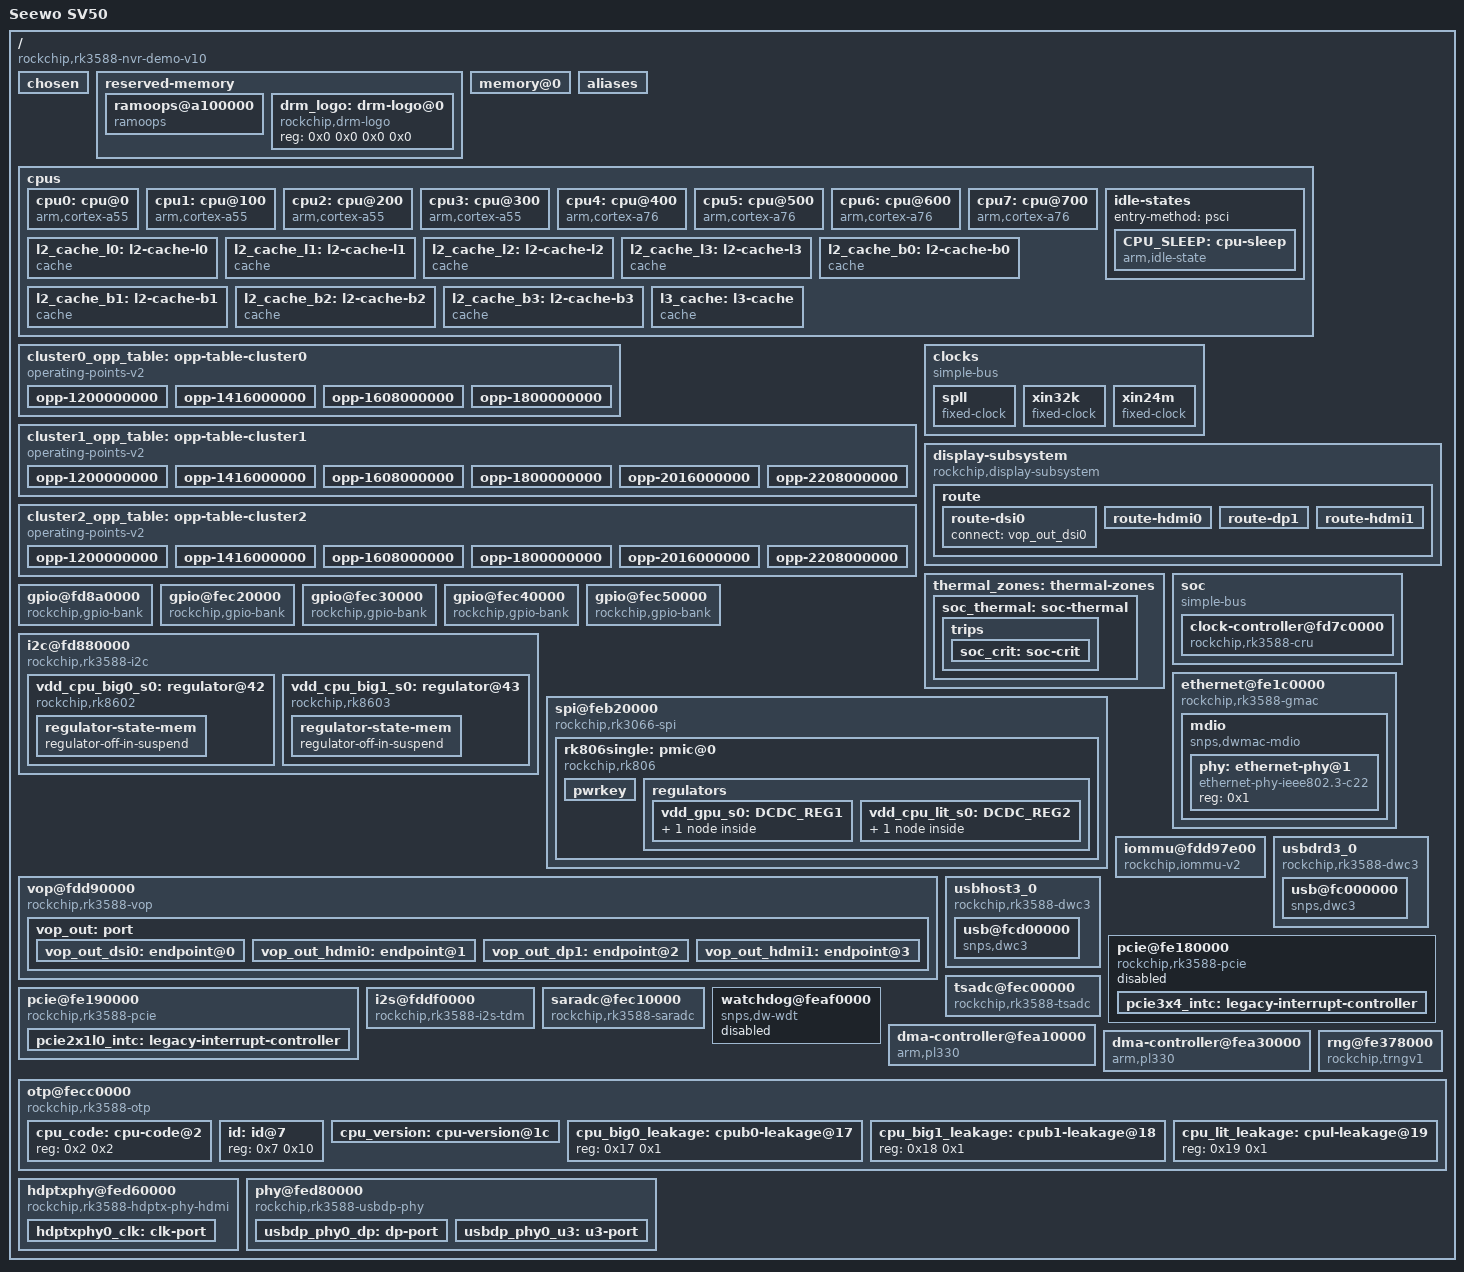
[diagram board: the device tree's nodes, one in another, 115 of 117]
// SPDX-License-Identifier: (GPL-2.0+ OR MIT)
/*
 * Device Tree Source for Rockchip RK3588 NVR Demo Board
 * Version: SV50 Board (AV.RK3588.71)
 * Converted to Linux 6.1 standard format
 */

/dts-v1/;

/ {
	compatible = "rockchip,rk3588-nvr-demo-v10", "rockchip,rk3588", "seewo,sv50";
	interrupt-parent = <&gic>;
	#address-cells = <2>;
	#size-cells = <2>;
	model = "Seewo SV50";

	chosen {
		bootargs = "storagemedia=emmc rw rootwait earlycon=uart8250,mmio32,0xfeb50000 console=ttyFIQ0 irqchip.gicv3_pseudo_nmi=0 clk_gate.always_on=1 pm_domains.always_on=1";
		stdout-path = "serial0:1500000n8";
	};

	reserved-memory {
		#address-cells = <2>;
		#size-cells = <2>;
		ranges;

		/* Reserved region from original DTB (0xa100000-0xa128000) */
		ramoops@a100000 {
			compatible = "ramoops";
			reg = <0x0 0x0a100000 0x0 0x0028000>;
			record-size = <0x10000>;
			console-size = <0x20000>;
			ftrace-size = <0x00000>;
			pmsg-size = <0x50000>;
		};

		/* DRM logo region */
		drm_logo: drm-logo@0 {
			compatible = "rockchip,drm-logo";
			reg = <0x0 0x0 0x0 0x0>;
		};
	};

	memory@0 {
		device_type = "memory";
		reg = <0x0 0x00200000 0x0 0x08200000>,
		      <0x0 0x09400000 0x0 0xe6c00000>;
	};

	aliases {
		serial0 = &uart0;
		serial2 = &uart2;
		serial5 = &uart5;
		i2c0 = &i2c0;
		i2c1 = &i2c1;
		i2c3 = &i2c3;
		i2c5 = &i2c5;
		i2c6 = &i2c6;
		spi2 = &spi2;
		dsi0 = &dsi0;
		dp1 = &dp1;
		hdmi0 = &hdmi0;
		hdmi1 = &hdmi1;
		ethernet1 = &gmac1;
		gpio0 = &gpio0;
		gpio1 = &gpio1;
		gpio2 = &gpio2;
		gpio3 = &gpio3;
		gpio4 = &gpio4;
		rkcif_mipi_lvds1 = &rkcif_mipi_lvds1;
		rkcif_mipi_lvds4 = &rkcif_mipi_lvds4;
		rkvenc0 = &rkvenc0;
		rkvenc1 = &rkvenc1;
		jpege0 = &jpege0;
		jpege1 = &jpege1;
		jpege2 = &jpege2;
		jpege3 = &jpege3;
		csi2dcphy1 = &csi2_dcphy1;
		csi2dphy1 = &csi2_dphy1;
		csi2dphy3 = &csi2_dphy3;
		hdptx0 = &hdptxphy0;
		hdptx1 = &hdptxphy1;
		hdptxhdmi0 = &hdmi_phy0;
		hdptxhdmi1 = &hdmi_phy1;
		usbdp0 = &usbdp_phy0;
		usbdp1 = &usbdp_phy1;
	};

	cpus {
		#address-cells = <1>;
		#size-cells = <0>;

		cpu0: cpu@0 {
			device_type = "cpu";
			compatible = "arm,cortex-a55";
			reg = <0x0>;
			enable-method = "psci";
			capacity-dmips-mhz = <530>;
			clocks = <&scmi_clk 0>;
			operating-points-v2 = <&cluster0_opp_table>;
			cpu-idle-states = <&CPU_SLEEP>;
			i-cache-size = <0x8000>;
			i-cache-line-size = <0x40>;
			i-cache-sets = <0x80>;
			d-cache-size = <0x8000>;
			d-cache-line-size = <0x40>;
			d-cache-sets = <0x80>;
			next-level-cache = <&l2_cache_l0>;
			#cooling-cells = <2>;
			dynamic-power-coefficient = <228>;
			cpu-supply = <&vdd_cpu_lit_s0>;
			mem-supply = <&vdd_cpu_lit_s0>;
		};

		cpu1: cpu@100 {
			device_type = "cpu";
			compatible = "arm,cortex-a55";
			reg = <0x100>;
			enable-method = "psci";
			capacity-dmips-mhz = <530>;
			clocks = <&scmi_clk 0>;
			operating-points-v2 = <&cluster0_opp_table>;
			cpu-idle-states = <&CPU_SLEEP>;
			i-cache-size = <0x8000>;
			i-cache-line-size = <0x40>;
			i-cache-sets = <0x80>;
			d-cache-size = <0x8000>;
			d-cache-line-size = <0x40>;
			d-cache-sets = <0x80>;
			next-level-cache = <&l2_cache_l1>;
		};

		cpu2: cpu@200 {
			device_type = "cpu";
			compatible = "arm,cortex-a55";
			reg = <0x200>;
			enable-method = "psci";
			capacity-dmips-mhz = <530>;
			clocks = <&scmi_clk 0>;
			operating-points-v2 = <&cluster0_opp_table>;
			cpu-idle-states = <&CPU_SLEEP>;
			i-cache-size = <0x8000>;
			i-cache-line-size = <0x40>;
			i-cache-sets = <0x80>;
			d-cache-size = <0x8000>;
			d-cache-line-size = <0x40>;
			d-cache-sets = <0x80>;
			next-level-cache = <&l2_cache_l2>;
		};

		cpu3: cpu@300 {
			device_type = "cpu";
			compatible = "arm,cortex-a55";
			reg = <0x300>;
			enable-method = "psci";
			capacity-dmips-mhz = <530>;
			clocks = <&scmi_clk 0>;
			operating-points-v2 = <&cluster0_opp_table>;
			cpu-idle-states = <&CPU_SLEEP>;
			i-cache-size = <0x8000>;
			i-cache-line-size = <0x40>;
			i-cache-sets = <0x80>;
			d-cache-size = <0x8000>;
			d-cache-line-size = <0x40>;
			d-cache-sets = <0x80>;
			next-level-cache = <&l2_cache_l3>;
		};

		cpu4: cpu@400 {
			device_type = "cpu";
			compatible = "arm,cortex-a76";
			reg = <0x400>;
			enable-method = "psci";
			capacity-dmips-mhz = <1024>;
			clocks = <&scmi_clk 2>;
			operating-points-v2 = <&cluster1_opp_table>;
			cpu-idle-states = <&CPU_SLEEP>;
			i-cache-size = <0x10000>;
			i-cache-line-size = <0x40>;
			i-cache-sets = <0x100>;
			d-cache-size = <0x10000>;
			d-cache-line-size = <0x40>;
			d-cache-sets = <0x100>;
			next-level-cache = <&l2_cache_b0>;
			#cooling-cells = <2>;
			dynamic-power-coefficient = <416>;
			cpu-supply = <&vdd_cpu_big0_s0>;
			mem-supply = <&vdd_cpu_big0_s0>;
		};

		cpu5: cpu@500 {
			device_type = "cpu";
			compatible = "arm,cortex-a76";
			reg = <0x500>;
			enable-method = "psci";
			capacity-dmips-mhz = <1024>;
			clocks = <&scmi_clk 2>;
			operating-points-v2 = <&cluster1_opp_table>;
			cpu-idle-states = <&CPU_SLEEP>;
			i-cache-size = <0x10000>;
			i-cache-line-size = <0x40>;
			i-cache-sets = <0x100>;
			d-cache-size = <0x10000>;
			d-cache-line-size = <0x40>;
			d-cache-sets = <0x100>;
			next-level-cache = <&l2_cache_b1>;
		};

		cpu6: cpu@600 {
			device_type = "cpu";
			compatible = "arm,cortex-a76";
			reg = <0x600>;
			enable-method = "psci";
			capacity-dmips-mhz = <1024>;
			clocks = <&scmi_clk 3>;
			operating-points-v2 = <&cluster2_opp_table>;
			cpu-idle-states = <&CPU_SLEEP>;
			i-cache-size = <0x10000>;
			i-cache-line-size = <0x40>;
			i-cache-sets = <0x100>;
			d-cache-size = <0x10000>;
			d-cache-line-size = <0x40>;
			d-cache-sets = <0x100>;
			next-level-cache = <&l2_cache_b2>;
			#cooling-cells = <2>;
			dynamic-power-coefficient = <416>;
			cpu-supply = <&vdd_cpu_big1_s0>;
			mem-supply = <&vdd_cpu_big1_s0>;
		};

		cpu7: cpu@700 {
			device_type = "cpu";
			compatible = "arm,cortex-a76";
			reg = <0x700>;
			enable-method = "psci";
			capacity-dmips-mhz = <1024>;
			clocks = <&scmi_clk 3>;
			operating-points-v2 = <&cluster2_opp_table>;
			cpu-idle-states = <&CPU_SLEEP>;
			i-cache-size = <0x10000>;
			i-cache-line-size = <0x40>;
			i-cache-sets = <0x100>;
			d-cache-size = <0x10000>;
			d-cache-line-size = <0x40>;
			d-cache-sets = <0x100>;
			next-level-cache = <&l2_cache_b3>;
		};

		idle-states {
			entry-method = "psci";

			CPU_SLEEP: cpu-sleep {
				compatible = "arm,idle-state";
				local-timer-stop;
				arm,psci-suspend-param = <0x0010000>;
				entry-latency-us = <100>;
				exit-latency-us = <250>;
				min-residency-us = <1500>;
			};
		};

		l2_cache_l0: l2-cache-l0 {
			compatible = "cache";
			cache-size = <0x20000>;
			cache-line-size = <0x40>;
			cache-sets = <0x200>;
			next-level-cache = <&l3_cache>;
		};

		l2_cache_l1: l2-cache-l1 {
			compatible = "cache";
			cache-size = <0x20000>;
			cache-line-size = <0x40>;
			cache-sets = <0x200>;
			next-level-cache = <&l3_cache>;
		};

		l2_cache_l2: l2-cache-l2 {
			compatible = "cache";
			cache-size = <0x20000>;
			cache-line-size = <0x40>;
			cache-sets = <0x200>;
			next-level-cache = <&l3_cache>;
		};

		l2_cache_l3: l2-cache-l3 {
			compatible = "cache";
			cache-size = <0x20000>;
			cache-line-size = <0x40>;
			cache-sets = <0x200>;
			next-level-cache = <&l3_cache>;
		};

		l2_cache_b0: l2-cache-b0 {
			compatible = "cache";
			cache-size = <0x80000>;
			cache-line-size = <0x40>;
			cache-sets = <0x400>;
			next-level-cache = <&l3_cache>;
		};

		l2_cache_b1: l2-cache-b1 {
			compatible = "cache";
			cache-size = <0x80000>;
			cache-line-size = <0x40>;
			cache-sets = <0x400>;
			next-level-cache = <&l3_cache>;
		};

		l2_cache_b2: l2-cache-b2 {
			compatible = "cache";
			cache-size = <0x80000>;
			cache-line-size = <0x40>;
			cache-sets = <0x400>;
			next-level-cache = <&l3_cache>;
		};

		l2_cache_b3: l2-cache-b3 {
			compatible = "cache";
			cache-size = <0x80000>;
			cache-line-size = <0x40>;
			cache-sets = <0x400>;
			next-level-cache = <&l3_cache>;
		};

		l3_cache: l3-cache {
			compatible = "cache";
			cache-size = <0x300000>;
			cache-line-size = <0x40>;
			cache-sets = <0x1000>;
		};
	};

	cluster0_opp_table: opp-table-cluster0 {
		compatible = "operating-points-v2";
		opp-shared;
		nvmem-cells = <&cpu_lit_leakage>;
		nvmem-cell-names = "leakage";
		rockchip,pvtm-voltage-sel = <
			0    1354    0
			1355 1434    1
			1435 1490    2
			1491 1546    3
			1547 1602    4
			1603 1658    5
			1659 9999    6
		>;
		rockchip,pvtm-pvtpll;
		rockchip,pvtm-offset = <0x64>;
		rockchip,pvtm-sample-time = <1100>;
		rockchip,pvtm-freq = <1416000>;
		rockchip,pvtm-volt = <750000>;
		rockchip,pvtm-ref-temp = <25>;
		rockchip,pvtm-temp-prop = <244 244>;
		rockchip,pvtm-thermal-zone = "soc-thermal";
		rockchip,grf = <&litcore_grf>;
		rockchip,reboot-freq = <1416000>;
		rockchip,temp-hysteresis = <5000>;
		rockchip,low-temp = <10000>;
		rockchip,low-temp-min-volt = <750000>;
		rockchip,high-temp = <85000>;
		rockchip,high-temp-max-freq = <1608000>;

		opp-1200000000 {
			opp-hz = /bits/ 64 <1200000000>;
			opp-microvolt = <700000 700000 950000>;
		};

		opp-1416000000 {
			opp-hz = /bits/ 64 <1416000000>;
			opp-microvolt = <762500 762500 950000>;
		};

		opp-1608000000 {
			opp-hz = /bits/ 64 <1608000000>;
			opp-microvolt = <850000 850000 950000>;
		};

		opp-1800000000 {
			opp-hz = /bits/ 64 <1800000000>;
			opp-microvolt = <950000 950000 950000>;
		};
	};

	cluster1_opp_table: opp-table-cluster1 {
		compatible = "operating-points-v2";
		opp-shared;
		nvmem-cells = <&cpu_big0_leakage>;
		nvmem-cell-names = "leakage";
		rockchip,pvtm-voltage-sel = <
			0    1640    0
			1641 1675    1
			1676 1710    2
			1711 1743    3
			1744 1776    4
			1777 9999    5
		>;
		rockchip,pvtm-pvtpll;
		rockchip,pvtm-offset = <0x18>;
		rockchip,pvtm-sample-time = <1100>;
		rockchip,pvtm-freq = <1608000>;
		rockchip,pvtm-volt = <750000>;
		rockchip,pvtm-ref-temp = <25>;
		rockchip,pvtm-temp-prop = <270 270>;
		rockchip,pvtm-thermal-zone = "soc-thermal";
		rockchip,grf = <&bigcore0_grf>;
		volt-mem-read-margin = <
			855000	1
			765000	2
			675000	3
			495000	4
		>;
		low-volt-mem-read-margin = <4>;
		intermediate-threshold-freq = <1008000>;
		rockchip,reboot-freq = <1800000>;
		rockchip,temp-hysteresis = <5000>;
		rockchip,low-temp = <10000>;
		rockchip,low-temp-min-volt = <750000>;
		rockchip,high-temp = <85000>;
		rockchip,high-temp-max-freq = <2208000>;

		opp-1200000000 {
			opp-hz = /bits/ 64 <1200000000>;
			opp-microvolt = <675000 675000 1000000>;
		};

		opp-1416000000 {
			opp-hz = /bits/ 64 <1416000000>;
			opp-microvolt = <700000 700000 1000000>;
		};

		opp-1608000000 {
			opp-hz = /bits/ 64 <1608000000>;
			opp-microvolt = <750000 750000 1000000>;
		};

		opp-1800000000 {
			opp-hz = /bits/ 64 <1800000000>;
			opp-microvolt = <825000 825000 1000000>;
		};

		opp-2016000000 {
			opp-hz = /bits/ 64 <2016000000>;
			opp-microvolt = <900000 900000 1000000>;
		};

		opp-2208000000 {
			opp-hz = /bits/ 64 <2208000000>;
			opp-microvolt = <975000 975000 1000000>;
		};
	};

	cluster2_opp_table: opp-table-cluster2 {
		compatible = "operating-points-v2";
		opp-shared;
		nvmem-cells = <&cpu_big1_leakage>;
		nvmem-cell-names = "leakage";
		rockchip,pvtm-voltage-sel = <
			0    1640    0
			1641 1675    1
			1676 1710    2
			1711 1743    3
			1744 1776    4
			1777 9999    5
		>;
		rockchip,pvtm-pvtpll;
		rockchip,pvtm-offset = <0x18>;
		rockchip,pvtm-sample-time = <1100>;
		rockchip,pvtm-freq = <1608000>;
		rockchip,pvtm-volt = <750000>;
		rockchip,pvtm-ref-temp = <25>;
		rockchip,pvtm-temp-prop = <270 270>;
		rockchip,pvtm-thermal-zone = "soc-thermal";
		rockchip,grf = <&bigcore1_grf>;
		volt-mem-read-margin = <
			855000	1
			765000	2
			675000	3
			495000	4
		>;
		low-volt-mem-read-margin = <4>;
		intermediate-threshold-freq = <1008000>;
		rockchip,reboot-freq = <1800000>;
		rockchip,temp-hysteresis = <5000>;
		rockchip,low-temp = <10000>;
		rockchip,low-temp-min-volt = <750000>;
		rockchip,high-temp = <85000>;
		rockchip,high-temp-max-freq = <2208000>;

		opp-1200000000 {
			opp-hz = /bits/ 64 <1200000000>;
			opp-microvolt = <675000 675000 1000000>;
		};

		opp-1416000000 {
			opp-hz = /bits/ 64 <1416000000>;
			opp-microvolt = <700000 700000 1000000>;
		};

		opp-1608000000 {
			opp-hz = /bits/ 64 <1608000000>;
			opp-microvolt = <750000 750000 1000000>;
		};

		opp-1800000000 {
			opp-hz = /bits/ 64 <1800000000>;
			opp-microvolt = <825000 825000 1000000>;
		};

		opp-2016000000 {
			opp-hz = /bits/ 64 <2016000000>;
			opp-microvolt = <900000 900000 1000000>;
		};

		opp-2208000000 {
			opp-hz = /bits/ 64 <2208000000>;
			opp-microvolt = <975000 975000 1000000>;
		};
	};


	clocks {
		compatible = "simple-bus";
		#address-cells = <2>;
		#size-cells = <2>;
		ranges;

		spll: spll {
			compatible = "fixed-clock";
			#clock-cells = <0>;
			clock-frequency = <700000000>;
			clock-output-names = "spll";
		};

		xin32k: xin32k {
			compatible = "fixed-clock";
			#clock-cells = <0>;
			clock-frequency = <32768>;
			clock-output-names = "xin32k";
		};

		xin24m: xin24m {
			compatible = "fixed-clock";
			#clock-cells = <0>;
			clock-frequency = <24000000>;
			clock-output-names = "xin24m";
		};
	};

	display-subsystem {
		compatible = "rockchip,display-subsystem";
		ports = <&vop_out>;
		clocks = <&hdptxphy0>, <&hdptxphy1>;
		clock-names = "hdmi0_phy_pll", "hdmi1_phy_pll";
		memory-region = <&drm_logo>;
		memory-region-names = "drm-logo";

route {
		route-dsi0 {
			status = "okay";
			connect = <&vop_out_dsi0>;
		};

		route-hdmi0 {
			status = "okay";
			connect = <&vop_out_hdmi0>;
			force-output;
		};

		route-dp1 {
			status = "okay";
			connect = <&vop_out_dp1>;
			force-output;
		};

		route-hdmi1 {
			status = "okay";
			connect = <&vop_out_hdmi1>;
			force-output;
		};
	};
};

	thermal_zones: thermal-zones {
	soc_thermal: soc-thermal {
		polling-delay-passive = <20>;
		polling-delay = <1000>;
		sustainable-power = <2100>;
		thermal-sensors = <&tsadc 0>;

		trips {
			soc_crit: soc-crit {
				temperature = <115000>;
				hysteresis = <2000>;
				type = "critical";
			};
		};
	};
};

/* SOC节点定义开始 */
soc {
	compatible = "simple-bus";
	#address-cells = <2>;
	#size-cells = <2>;
	ranges;
dtc -I dts -O dtb -o rk3588-smart-am60.dtb rk3588-smart-am60.dts
		/* 时钟控制器 */
	cru: clock-controller@fd7c0000 {
		compatible = "rockchip,rk3588-cru";
		rockchip,grf = <&php_grf>;
		reg = <0x0 0xfd7c0000 0x0 0x5c000>;
		#clock-cells = <1>;
		#reset-cells = <1>;
		assigned-clocks = <&cru PLL_GPLL>,
				  <&cru PLL_CPLL>,
				  <&cru PLL_NPLL>,
				  <&cru ACLK_BUS_ROOT>,
				  <&cru HCLK_BUS_ROOT>,
				  <&cru ACLK_TOP_ROOT>,
				  <&cru PCLK_TOP_ROOT>;
		assigned-clock-rates = <1200000000>,
				       <1000000000>,
				       <850000000>,
				       <500000000>,
				       <200000000>,
				       <400000000>,
				       <100000000>;
	};
};

/* GPIO */
&gpio0: gpio@fd8a0000 {
	compatible = "rockchip,gpio-bank";
	reg = <0x00 0xfd8a0000 0x00 0x100>;
	interrupts = <0x00 0x115 0x04>;
	clocks = <0x02 0x284 0x02 0x285>;
	gpio-controller;
	#gpio-cells = <0x02>;
	gpio-ranges = <0x16e 0x00 0x00 0x20>;
	interrupt-controller;
	#interrupt-cells = <0x02>;
};

&gpio1: gpio@fec20000 {
	compatible = "rockchip,gpio-bank";
	reg = <0x00 0xfec20000 0x00 0x100>;
	interrupts = <0x00 0x116 0x04>;
	clocks = <0x02 0x7d 0x02 0x7e>;
	gpio-controller;
	#gpio-cells = <0x02>;
	gpio-ranges = <0x16e 0x00 0x20 0x20>;
	interrupt-controller;
	#interrupt-cells = <0x02>;
};

&gpio2: gpio@fec30000 {
	compatible = "rockchip,gpio-bank";
	reg = <0x00 0xfec30000 0x00 0x100>;
	interrupts = <0x00 0x117 0x04>;
	clocks = <0x02 0x7f 0x02 0x80>;
	gpio-controller;
	#gpio-cells = <0x02>;
	gpio-ranges = <0x16e 0x00 0x40 0x20>;
	interrupt-controller;
	#interrupt-cells = <0x02>;
};

&gpio3: gpio@fec40000 {
	compatible = "rockchip,gpio-bank";
	reg = <0x00 0xfec40000 0x00 0x100>;
	interrupts = <0x00 0x118 0x04>;
	clocks = <0x02 0x81 0x02 0x82>;
	gpio-controller;
	#gpio-cells = <0x02>;
	gpio-ranges = <0x16e 0x00 0x60 0x20>;
	interrupt-controller;
	#interrupt-cells = <0x02>;
};

&gpio4: gpio@fec50000 {
	compatible = "rockchip,gpio-bank";
	reg = <0x00 0xfec50000 0x00 0x100>;
	interrupts = <0x00 0x119 0x04>;
	clocks = <0x02 0x83 0x02 0x84>;
	gpio-controller;
	#gpio-cells = <0x02>;
	gpio-ranges = <0x16e 0x00 0x80 0x20>;
	interrupt-controller;
	#interrupt-cells = <0x02>;
};

/* I2C控制器 - 由于长度限制，这里只展示i2c0的完整配置 */
&i2c0: i2c@fd880000 {
	compatible = "rockchip,rk3588-i2c", "rockchip,rk3399-i2c";
	reg = <0x0 0xfd880000 0x0 0x1000>;
	clocks = <&cru CLK_I2C0>, <&cru PCLK_I2C0>;
	clock-names = "i2c", "pclk";
	interrupts = <GIC_SPI 317 IRQ_TYPE_LEVEL_HIGH>;
	pinctrl-names = "default";
	pinctrl-0 = <&i2c0m0_xfer>;
	#address-cells = <1>;
	#size-cells = <0>;
	status = "okay";

	vdd_cpu_big0_s0: regulator@42 {
		compatible = "rockchip,rk8602";
		reg = <0x42>;
		vin-supply = <&vcc5v0_sys>;
		regulator-name = "vdd_cpu_big0_s0";
		regulator-min-microvolt = <550000>;
		regulator-max-microvolt = <1050000>;
		regulator-ramp-delay = <2300>;
		rockchip,suspend-voltage-selector = <1>;
		regulator-boot-on;
		regulator-always-on;
		regulator-state-mem {
			regulator-off-in-suspend;
		};
	};

	vdd_cpu_big1_s0: regulator@43 {
		compatible = "rockchip,rk8603";
		reg = <0x43>;
		vin-supply = <&vcc5v0_sys>;
		regulator-name = "vdd_cpu_big1_s0";
		regulator-min-microvolt = <550000>;
		regulator-max-microvolt = <1050000>;
		regulator-ramp-delay = <2300>;
		rockchip,suspend-voltage-selector = <1>;
		regulator-boot-on;
		regulator-always-on;
		regulator-state-mem {
			regulator-off-in-suspend;
		};
	};
};

/* SPI控制器 */
&spi2: spi@feb20000 {
	compatible = "rockchip,rk3066-spi";
	reg = <0x0 0xfeb20000 0x0 0x1000>;
	interrupts = <GIC_SPI 328 IRQ_TYPE_LEVEL_HIGH>;
	#address-cells = <1>;
	#size-cells = <0>;
	clocks = <&cru CLK_SPI2>, <&cru PCLK_SPI2>;
	clock-names = "spiclk", "apb_pclk";
	dmas = <&dmac2 15>, <&dmac2 16>;
	dma-names = "tx", "rx";
	pinctrl-names = "default";
	pinctrl-0 = <&spi2m0_cs0 &spi2m0_pins>;
	num-cs = <1>;
	status = "okay";
	assigned-clocks = <&cru CLK_SPI2>;
	assigned-clock-rates = <200000000>;

	rk806single: pmic@0 {
		compatible = "rockchip,rk806";
		spi-max-frequency = <1000000>;
		reg = <0x0>;
		interrupt-parent = <&gpio0>;
		interrupts = <7 IRQ_TYPE_LEVEL_LOW>;
		pinctrl-names = "default", "pmic-power-off";
		pinctrl-0 = <&pmic_pins>, <&rk806_dvs1_null>,
			    <&rk806_dvs2_null>, <&rk806_dvs3_null>;
		pinctrl-1 = <&rk806_dvs1_slp>, <&rk806_dvs2_null>,
			    <&rk806_dvs3_null>;
		low_voltage_threshold = <3000>;
		shutdown_voltage_threshold = <2700>;
		shutdown_temperture_threshold = <160>;
		hotdie_temperture_threshold = <115>;
		pmic-reset-func = <1>;
		vcc1-supply = <&vcc5v0_sys>;
		vcc2-supply = <&vcc5v0_sys>;
		vcc3-supply = <&vcc5v0_sys>;
		vcc4-supply = <&vcc5v0_sys>;
		vcc5-supply = <&vcc5v0_sys>;
		vcc6-supply = <&vcc5v0_sys>;
		vcc7-supply = <&vcc5v0_sys>;
		vcc8-supply = <&vcc5v0_sys>;
		vcc9-supply = <&vcc5v0_sys>;
		vcc10-supply = <&vcc5v0_sys>;
		vcc11-supply = <&vcc_2v0_pldo_s3>;
		vcc12-supply = <&vcc5v0_sys>;
		vcc13-supply = <&vcc_1v8_s3>;
		vcc14-supply = <&vcc_1v8_s3>;
		vcca-supply = <&vcc5v0_sys>;

		pwrkey {
			status = "okay";
		};

		regulators {
			vdd_gpu_s0: DCDC_REG1 {
				regulator-always-on;
				regulator-boot-on;
				regulator-min-microvolt = <550000>;
				regulator-max-microvolt = <950000>;
				regulator-ramp-delay = <12500>;
				regulator-name = "vdd_gpu_s0";
				regulator-state-mem {
					regulator-off-in-suspend;
				};
			};

			vdd_cpu_lit_s0: DCDC_REG2 {
				regulator-always-on;
				regulator-boot-on;
				regulator-min-microvolt = <550000>;
				regulator-max-microvolt = <950000>;
				regulator-ramp-delay = <12500>;
				regulator-name = "vdd_cpu_lit_s0";
				regulator-state-mem {
					regulator-off-in-suspend;
				};
			};
		};
	};
};

/* 以太网控制器 */
&gmac1: ethernet@fe1c0000 {
	compatible = "rockchip,rk3588-gmac", "snps,dwmac-4.20a";
	reg = <0x0 0xfe1c0000 0x0 0x10000>;
	interrupts = <GIC_SPI 234 IRQ_TYPE_LEVEL_HIGH>,
		     <GIC_SPI 233 IRQ_TYPE_LEVEL_HIGH>;
	interrupt-names = "macirq", "eth_wake_irq";
	rockchip,grf = <&sys_grf>;
	rockchip,php_grf = <&php_grf>;
	clocks = <&cru CLK_GMAC_125M>, <&cru CLK_GMAC_50M>,
		 <&cru PCLK_GMAC1>, <&cru ACLK_GMAC1>,
		 <&cru CLK_GMAC1_PTP_REF>;
	clock-names = "stmmaceth", "clk_mac_ref",
		      "pclk_mac", "aclk_mac", "ptp_ref";
	resets = <&cru SRST_A_GMAC1>;
	reset-names = "stmmaceth";
	power-domains = <&power RK3588_PD_GMAC>;
	snps,mixed-burst;
	snps,tso;
	snps,axi-config = <&gmac1_stmmac_axi_setup>;
	snps,mtl-rx-config = <&gmac1_mtl_rx_setup>;
	snps,mtl-tx-config = <&gmac1_mtl_tx_setup>;
	status = "okay";
	phy-mode = "rgmii";
	clock_in_out = "output";
	snps,reset-gpio = <&gpio3 RK_PB7 GPIO_ACTIVE_LOW>;
			snps,reset-active-high;
	snps,reset-delays-us = <0 20000 100000>;
	pinctrl-names = "default";
	pinctrl-0 = <&gmac1_miim
		     &gmac1_tx_bus2
		     &gmac1_rx_bus2
		     &gmac1_rgmii_clk
		     &gmac1_rgmii_bus>;
	tx_delay = <0x42>;
	rx_delay = <0x4f>;
	fixed-link = <1 1 1000 1 1>;

	mdio {
		compatible = "snps,dwmac-mdio";
		#address-cells = <1>;
		#size-cells = <0>;
		status = "okay";

		phy: ethernet-phy@1 {
			compatible = "ethernet-phy-ieee802.3-c22";
			reg = <0x1>;
		};
	};
};

/* 显示控制器 */
&vop: vop@fdd90000 {
	compatible = "rockchip,rk3588-vop";
	reg = <0x0 0xfdd90000 0x0 0x4200>,
	      <0x0 0xfdd95000 0x0 0x1000>;
	reg-names = "regs", "gamma_lut";
	interrupts = <GIC_SPI 156 IRQ_TYPE_LEVEL_HIGH>;
	clocks = <&cru ACLK_VOP>,
		 <&cru HCLK_VOP>,
		 <&cru DCLK_VP0>,
		 <&cru DCLK_VP1>,
		 <&cru DCLK_VP2>,
		 <&cru DCLK_VP3>,
		 <&cru PCLK_VOP>;
	clock-names = "aclk_vop", "hclk_vop",
		      "dclk_vp0", "dclk_vp1",
		      "dclk_vp2", "dclk_vp3", "pclk_vop";
	resets = <&cru SRST_A_VOP>,
		 <&cru SRST_H_VOP>,
		 <&cru SRST_D_VP0>,
		 <&cru SRST_D_VP1>,
		 <&cru SRST_D_VP2>,
		 <&cru SRST_D_VP3>;
	reset-names = "axi", "ahb", "dclk_vp0",
		      "dclk_vp1", "dclk_vp2", "dclk_vp3";
	iommus = <&vop_mmu>;
	power-domains = <&power RK3588_PD_VOP>;
	rockchip,grf = <&sys_grf>;
	rockchip,vop-grf = <&vop_grf>;
	rockchip,vo1-grf = <&vo1_grf>;
	rockchip,pmu = <&pmu>;
	status = "okay";
	assigned-clocks = <&cru ACLK_VOP>;
	assigned-clock-rates = <800000000>;

	vop_out: port {
		#address-cells = <1>;
		#size-cells = <0>;

		vop_out_dsi0: endpoint@0 {
			reg = <0>;
			remote-endpoint = <&dsi0_in_vop>;
		};

		vop_out_hdmi0: endpoint@1 {
			reg = <1>;
			remote-endpoint = <&hdmi0_in_vop>;
		};

		vop_out_dp1: endpoint@2 {
			reg = <2>;
			remote-endpoint = <&dp1_in_vop>;
		};

		vop_out_hdmi1: endpoint@3 {
			reg = <3>;
			remote-endpoint = <&hdmi1_in_vop>;
		};
	};
};

&vop_mmu: iommu@fdd97e00 {
	compatible = "rockchip,iommu-v2";
	reg = <0x0 0xfdd97e00 0x0 0x100>,
	      <0x0 0xfdd97f00 0x0 0x100>;
	interrupts = <GIC_SPI 156 IRQ_TYPE_LEVEL_HIGH>;
	interrupt-names = "vop_mmu";
	clocks = <&cru ACLK_VOP>, <&cru HCLK_VOP>;
	clock-names = "aclk", "iface";
	#iommu-cells = <0>;
	rockchip,disable-device-link-resume;
	rockchip,shootdown-entire;
	status = "okay";
};

/* USB控制器 */
&usbdrd3_0: usbdrd3_0 {
	compatible = "rockchip,rk3588-dwc3", "rockchip,rk3399-dwc3";
	clocks = <&cru CLK_USB3OTG0_REF>, <&cru CLK_USB3OTG0_SUSPEND>,
		 <&cru CLK_USB3OTG0>;
	clock-names = "ref", "suspend", "bus";
	#address-cells = <2>;
	#size-cells = <2>;
	ranges;
	status = "okay";

	usb@fc000000 {
		compatible = "snps,dwc3";
		reg = <0x0 0xfc000000 0x0 0x400000>;
		interrupts = <GIC_SPI 220 IRQ_TYPE_LEVEL_HIGH>;
		power-domains = <&power RK3588_PD_USB>;
		resets = <&cru SRST_USB3OTG0>;
		reset-names = "usb3-otg";
		dr_mode = "peripheral";
		phys = <&u2phy0_otg>, <&usbdp_phy0_u3>;
		phy-names = "usb2-phy", "usb3-phy";
		phy_type = "utmi_wide";
		snps,dis_enblslpm_quirk;
		snps,dis-u1-entry-quirk;
		snps,dis-u2-entry-quirk;
		snps,dis-u2-freeclk-exists-quirk;
		snps,dis-del-phy-power-chg-quirk;
		snps,dis-tx-ipgap-linecheck-quirk;
		snps,parkmode-disable-ss-quirk;
		quirk-skip-phy-init;
		tx-fifo-resize;
		status = "okay";
	};
};

&usbhost3_0: usbhost3_0 {
	compatible = "rockchip,rk3588-dwc3", "rockchip,rk3399-dwc3";
	clocks = <&cru CLK_USB3OTG2_REF>, <&cru CLK_USB3OTG2_SUSPEND>,
		 <&cru CLK_USB3OTG2>, <&cru CLK_USB3OTG2>,
		 <&cru ACLK_USB_ROOT>, <&cru CLK_USB3OTG2>;
	clock-names = "ref", "suspend", "bus", "utmi", "php", "pipe";
	#address-cells = <2>;
	#size-cells = <2>;
	ranges;
	status = "okay";

	usb@fcd00000 {
		compatible = "snps,dwc3";
		reg = <0x0 0xfcd00000 0x0 0x400000>;
		interrupts = <GIC_SPI 222 IRQ_TYPE_LEVEL_HIGH>;
		resets = <&cru SRST_USB3OTG2>;
		reset-names = "usb3-host";
		dr_mode = "host";
		phys = <&usbdp_phy1_u3>;
		phy-names = "usb3-phy";
		phy_type = "utmi_wide";
		snps,dis_enblslpm_quirk;
		snps,dis-u2-freeclk-exists-quirk;
		snps,dis-del-phy-power-chg-quirk;
		snps,dis-tx-ipgap-linecheck-quirk;
		snps,dis_rxdet_inp3_quirk;
		snps,parkmode-disable-ss-quirk;
		status = "okay";
	};
};

/* PCIe控制器 */
&pcie3x4: pcie@fe180000 {
	compatible = "rockchip,rk3588-pcie", "snps,dw-pcie";
	#address-cells = <3>;
	#size-cells = <2>;
	bus-range = <0x30 0x3f>;
	clocks = <&cru ACLK_PCIE_4L_MSTR>, <&cru ACLK_PCIE_4L_SLV>,
		 <&cru ACLK_PCIE_4L_DBI>, <&cru PCLK_PCIE_4L>,
		 <&cru CLK_PCIE_AUX2>, <&cru CLK_PCIE4L_PIPE>;
	clock-names = "aclk_mst", "aclk_slv", "aclk_dbi", "pclk", "aux", "pipe";
	device_type = "pci";
	interrupts = <GIC_SPI 248 IRQ_TYPE_LEVEL_HIGH>,
		     <GIC_SPI 247 IRQ_TYPE_LEVEL_HIGH>,
		     <GIC_SPI 246 IRQ_TYPE_LEVEL_HIGH>,
		     <GIC_SPI 245 IRQ_TYPE_LEVEL_HIGH>,
		     <GIC_SPI 244 IRQ_TYPE_LEVEL_HIGH>;
	interrupt-names = "sys", "pmc", "msg", "legacy", "err";
	#interrupt-cells = <1>;
	interrupt-map-mask = <0x0 0x0 0x0 0x7>;
	interrupt-map = <0x0 0x0 0x0 0x1 &pcie3x4_intc 0>,
			<0x0 0x0 0x0 0x2 &pcie3x4_intc 1>,
			<0x0 0x0 0x0 0x3 &pcie3x4_intc 2>,
			<0x0 0x0 0x0 0x4 &pcie3x4_intc 3>;
	linux,pci-domain = <3>;
	num-ib-windows = <8>;
	num-ob-windows = <8>;
	num-viewport = <4>;
	max-link-speed = <2>;
	msi-map = <0x3000 &its 0x3000 0x1000>;
	num-lanes = <1>;
	phys = <&pcie30phy>;
	phy-names = "pcie-phy";
	ranges = <0x800 0x0 0xf3000000 0x0 0xf3000000 0x0 0x100000>,
		 <0x81000000 0x0 0xf3100000 0x0 0xf3100000 0x0 0x100000>,
		 <0x82000000 0x0 0xf3200000 0x0 0xf3200000 0x0 0xe00000>,
		 <0xc3000000 0x9 0xc0000000 0x9 0xc0000000 0x0 0x40000000>;
	reg = <0x0 0xfe180000 0x0 0x10000>,
	      <0xa 0x40c00000 0x0 0x400000>;
	reg-names = "pcie-apb", "pcie-dbi";
	resets = <&cru SRST_PCIE_4L_POWER_UP>, <&cru SRST_P_PCIE3>;
	reset-names = "pcie", "periph";
	rockchip,pipe-grf = <&php_grf>;
	status = "disable";
	reset-gpios = <&gpio4 RK_PA2 GPIO_ACTIVE_LOW>;
	rockchip,skip-scan-in-resume;

	pcie3x4_intc: legacy-interrupt-controller {
		interrupt-controller;
		#address-cells = <0>;
		#interrupt-cells = <1>;
		interrupt-parent = <&gic>;
		interrupts = <GIC_SPI 245 IRQ_TYPE_EDGE_RISING>;
	};
};

&pcie2x1l0: pcie@fe190000 {
	compatible = "rockchip,rk3588-pcie", "snps,dw-pcie";
	#address-cells = <3>;
	#size-cells = <2>;
	bus-range = <0x40 0x4f>;
	clocks = <&cru ACLK_PCIE_2L1_MSTR>, <&cru ACLK_PCIE_2L1_SLV>,
		 <&cru ACLK_PCIE_2L1_DBI>, <&cru PCLK_PCIE_2L1>,
		 <&cru CLK_PCIE_AUX3>, <&cru CLK_PCIE2L1_PIPE>;
	clock-names = "aclk_mst", "aclk_slv", "aclk_dbi", "pclk", "aux", "pipe";
	device_type = "pci";
	interrupts = <GIC_SPI 253 IRQ_TYPE_LEVEL_HIGH>,
		     <GIC_SPI 252 IRQ_TYPE_LEVEL_HIGH>,
		     <GIC_SPI 251 IRQ_TYPE_LEVEL_HIGH>,
		     <GIC_SPI 250 IRQ_TYPE_LEVEL_HIGH>,
		     <GIC_SPI 249 IRQ_TYPE_LEVEL_HIGH>;
	interrupt-names = "sys", "pmc", "msg", "legacy", "err";
	#interrupt-cells = <1>;
	interrupt-map-mask = <0x0 0x0 0x0 0x7>;
	interrupt-map = <0x0 0x0 0x0 0x1 &pcie2x1l0_intc 0>,
			<0x0 0x0 0x0 0x2 &pcie2x1l0_intc 1>,
			<0x0 0x0 0x0 0x3 &pcie2x1l0_intc 2>,
			<0x0 0x0 0x0 0x4 &pcie2x1l0_intc 3>;
	linux,pci-domain = <4>;
	num-ib-windows = <8>;
	num-ob-windows = <8>;
	num-viewport = <4>;
	max-link-speed = <2>;
	msi-map = <0x4000 &its 0x4000 0x1000>;
	num-lanes = <1>;
	phys = <&pcie30phy>;
	phy-names = "pcie-phy";
	ranges = <0x800 0x0 0xf4000000 0x0 0xf4000000 0x0 0x100000>,
		 <0x81000000 0x0 0xf4100000 0x0 0xf4100000 0x0 0x100000>,
		 <0x82000000 0x0 0xf4200000 0x0 0xf4200000 0x0 0xe00000>,
		 <0xc3000000 0xa 0x0 0xa 0x0 0x0 0x40000000>;
	reg = <0x0 0xfe190000 0x0 0x10000>,
	      <0xa 0x41000000 0x0 0x400000>;
	reg-names = "pcie-apb", "pcie-dbi";
	resets = <&cru SRST_PCIE_2L1_POWER_UP>, <&cru SRST_P_PCIE4>;
	reset-names = "pcie", "periph";
	rockchip,pipe-grf = <&php_grf>;
	status = "okay";

	pcie2x1l0_intc: legacy-interrupt-controller {
		interrupt-controller;
		#address-cells = <0>;
		#interrupt-cells = <1>;
		interrupt-parent = <&gic>;
		interrupts = <GIC_SPI 250 IRQ_TYPE_EDGE_RISING>;
	};
};

/* 音频接口 */
&i2s5_8ch: i2s@fddf0000 {
	compatible = "rockchip,rk3588-i2s-tdm";
	reg = <0x0 0xfddf0000 0x0 0x1000>;
	interrupts = <GIC_SPI 185 IRQ_TYPE_LEVEL_HIGH>;
	clocks = <&cru MCLK_I2S5_8CH_TX>, <&cru MCLK_I2S5_8CH_TX>,
		 <&cru HCLK_I2S5_8CH>;
	clock-names = "mclk_tx", "mclk_rx", "hclk";
	assigned-clocks = <&cru CLK_I2S5_8CH_TX_SRC>;
	assigned-clock-parents = <&cru PLL_AUPLL>;
	dmas = <&dmac2 2>;
	dma-names = "tx";
	power-domains = <&power RK3588_PD_AUDIO>;
	resets = <&cru SRST_M_I2S5_8CH_TX>;
	reset-names = "tx-m";
	rockchip,playback-only;
	#sound-dai-cells = <0>;
	status = "okay";
};

/* 温度传感器 */
&tsadc: tsadc@fec00000 {
	compatible = "rockchip,rk3588-tsadc";
	reg = <0x0 0xfec00000 0x0 0x400>;
	interrupts = <GIC_SPI 397 IRQ_TYPE_LEVEL_HIGH>;
	clocks = <&cru CLK_TSADC>, <&cru PCLK_TSADC>;
	clock-names = "tsadc", "apb_pclk";
	assigned-clocks = <&cru CLK_TSADC>;
	assigned-clock-rates = <2000000>;
	resets = <&cru SRST_TSADC>, <&cru SRST_P_TSADC>;
	reset-names = "tsadc", "tsadc-apb";
	#thermal-sensor-cells = <1>;
	rockchip,hw-tshut-temp = <120000>;
	rockchip,hw-tshut-mode = <0>;
	rockchip,hw-tshut-polarity = <0>;
	pinctrl-names = "gpio", "otpout";
	pinctrl-0 = <&tsadc_gpio_func>;
	pinctrl-1 = <&tsadc_shut>;
	status = "okay";
};

/* ADC */
&saradc: saradc@fec10000 {
	compatible = "rockchip,rk3588-saradc";
	reg = <0x0 0xfec10000 0x0 0x10000>;
	interrupts = <GIC_SPI 398 IRQ_TYPE_LEVEL_HIGH>;
	#io-channel-cells = <1>;
	clocks = <&cru CLK_SARADC>, <&cru PCLK_SARADC>;
	clock-names = "saradc", "apb_pclk";
	resets = <&cru SRST_P_SARADC>;
	reset-names = "saradc-apb";
	status = "okay";
	vref-supply = <&vcc_1v8_s0>;
};

/* 看门狗 */
&watchdog: watchdog@feaf0000 {
	compatible = "snps,dw-wdt";
	reg = <0x0 0xfeaf0000 0x0 0x100>;
	clocks = <&cru TCLK_WDT0>, <&cru PCLK_WDT0>;
	clock-names = "tclk", "pclk";
	interrupts = <GIC_SPI 315 IRQ_TYPE_LEVEL_HIGH>;
	status = "disabled";
};

/* DMA控制器 */
&dmac0: dma-controller@fea10000 {
	compatible = "arm,pl330", "arm,primecell";
	reg = <0x0 0xfea10000 0x0 0x4000>;
	interrupts = <GIC_SPI 86 IRQ_TYPE_LEVEL_HIGH>,
		     <GIC_SPI 87 IRQ_TYPE_LEVEL_HIGH>;
	clocks = <&cru ACLK_DMAC0>;
	clock-names = "apb_pclk";
	#dma-cells = <1>;
	arm,pl330-periph-burst;
};

&dmac2: dma-controller@fea30000 {
	compatible = "arm,pl330", "arm,primecell";
	reg = <0x0 0xfea30000 0x0 0x4000>;
	interrupts = <GIC_SPI 88 IRQ_TYPE_LEVEL_HIGH>,
		     <GIC_SPI 89 IRQ_TYPE_LEVEL_HIGH>;
	clocks = <&cru ACLK_DMAC2>;
	clock-names = "apb_pclk";
	#dma-cells = <1>;
	arm,pl330-periph-burst;
};

/* 随机数生成器 */
&rng: rng@fe378000 {
	compatible = "rockchip,trngv1";
	reg = <0x0 0xfe378000 0x0 0x200>;
	interrupts = <GIC_SPI 400 IRQ_TYPE_LEVEL_HIGH>;
	clocks = <&cru CLK_TRNG_NS>;
	clock-names = "hclk_trng";
	resets = <&scmi_reset 48>;
	reset-names = "reset";
	status = "okay";
};

/* OTP */
&otp: otp@fecc0000 {
	compatible = "rockchip,rk3588-otp";
	reg = <0x0 0xfecc0000 0x0 0x400>;
	#address-cells = <1>;
	#size-cells = <1>;
	clocks = <&cru CLK_OTPC_NS>, <&cru PCLK_OTPC_NS>,
		 <&cru CLK_OTPC_ARB>, <&cru CLK_OTPC_PHY>;
	clock-names = "otpc", "apb", "arb", "phy";
	resets = <&cru SRST_OTPC_NS>, <&cru SRST_P_OTPC_NS>,
		 <&cru SRST_OTPC_ARB>;
	reset-names = "otpc", "apb", "arb";

	cpu_code: cpu-code@2 {
		reg = <0x2 0x2>;
	};

	id: id@7 {
		reg = <0x7 0x10>;
	};

	cpu_version: cpu-version@1c {
		reg = <0x1c 0x1>;
		bits = <3 3>;
	};

	cpu_big0_leakage: cpub0-leakage@17 {
		reg = <0x17 0x1>;
	};

	cpu_big1_leakage: cpub1-leakage@18 {
		reg = <0x18 0x1>;
	};

	cpu_lit_leakage: cpul-leakage@19 {
		reg = <0x19 0x1>;
	};
};

/* HDMI PHY */
&hdptxphy0: hdptxphy@fed60000 {
	compatible = "rockchip,rk3588-hdptx-phy-hdmi";
	reg = <0x0 0xfed60000 0x0 0x2000>;
	clocks = <&cru CLK_USBDPPHY0_REF>, <&cru PCLK_HDMITX0>;
	clock-names = "ref", "apb";
	resets = <&cru SRST_HDMITX0>, <&cru SRST_P_HDMITX0>,
		 <&cru SRST_HDMITX0_INIT>, <&cru SRST_HDMITX0_CMN>,
		 <&cru SRST_HDMITX0_LANE>, <&cru SRST_HDMITX0_RO_PLL>,
		 <&cru SRST_HDMITX0_LC_PLL>;
	reset-names = "phy", "apb", "init", "cmn", "lane", "ropll", "lcpll";
	rockchip,grf = <&hdptxphy_grf>;
	#phy-cells = <0>;
	status = "okay";

	hdptxphy0_clk: clk-port {
		#clock-cells = <0>;
		status = "okay";
	};
};

/* USBDP PHY */
&usbdp_phy0: phy@fed80000 {
	compatible = "rockchip,rk3588-usbdp-phy";
	reg = <0x0 0xfed80000 0x0 0x10000>;
	rockchip,u2phy-grf = <&usb2phy0_grf>;
	rockchip,usb-grf = <&usb_grf>;
	rockchip,usbdpphy-grf = <&usbdpphy_grf>;
	rockchip,vo-grf = <&vo0_grf>;
	clocks = <&cru CLK_USBDPPHY0_REF>, <&cru CLK_USBDP_GRF0>,
		 <&cru PCLK_USBDPPHY0>, <&cru CLK_USBDP_CMN_REF>;
	clock-names = "refclk", "immortal", "pclk", "utmi";
	resets = <&cru SRST_USBDP_COMBO_PHY0_INIT>,
		 <&cru SRST_USBDP_COMBO_PHY0_CMN>,
		 <&cru SRST_USBDP_COMBO_PHY0_LANE>,
		 <&cru SRST_USBDP_COMBO_PHY0_PCS>,
		 <&cru SRST_P_USBDPPHY0>;
	reset-names = "init", "cmn", "lane", "pcs_apb", "pma_apb";
	status = "okay";
	orientation-switch;
	svid = <0xff01>;
	sbu1-dc-gpios = <&gpio0 22 GPIO_ACTIVE_HIGH>;
	sbu2-dc-gpios = <&gpio0 27 GPIO_ACTIVE_HIGH>;

	usbdp_phy0_dp: dp-port {
		#phy-cells = <0>;
		status = "okay";
	};

	usbdp_phy0_u3: u3-port {
		#phy-cells = <0>;
		status = "okay";
	};
};
};


